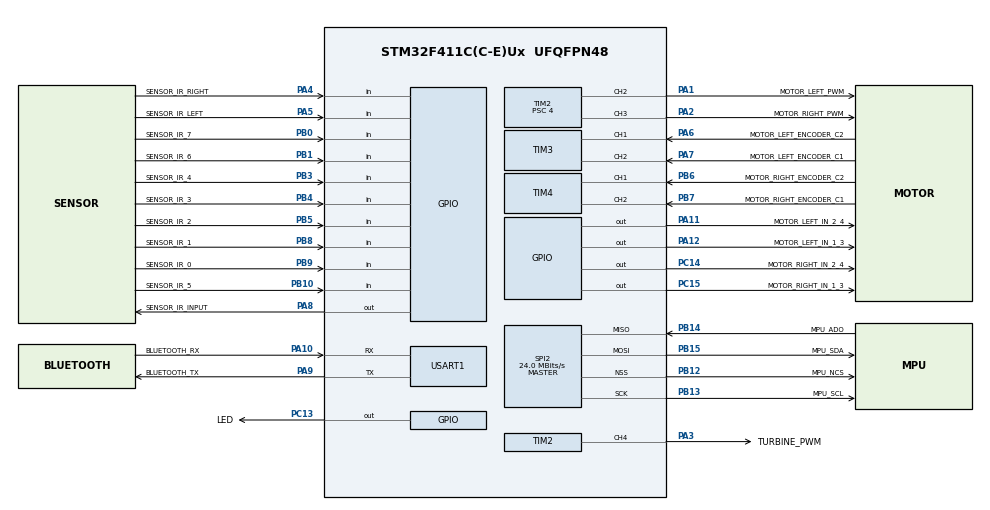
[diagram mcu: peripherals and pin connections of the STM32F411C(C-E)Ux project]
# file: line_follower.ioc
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Mcu.Family=STM32F4
Mcu.Name=STM32F411C(C-E)Ux
Mcu.Package=UFQFPN48
NVIC.PriorityGroup=NVIC_PRIORITYGROUP_4
NVIC.USART1_IRQn=true\:0\:0\:true\:false\:true\:true\:true\:true
PA1.GPIO_Label=MOTOR_LEFT_PWM
PA1.Signal=S_TIM2_CH2
PA10.GPIO_Label=BLUETOOTH_RX
PA10.Mode=Asynchronous
PA10.Signal=USART1_RX
PA11.GPIO_Label=MOTOR_LEFT_IN_2_4
PA11.Signal=GPIO_Output
PA12.GPIO_Label=MOTOR_LEFT_IN_1_3
PA12.Signal=GPIO_Output
PA2.GPIO_Label=MOTOR_RIGHT_PWM
PA2.Signal=S_TIM2_CH3
PA3.GPIO_Label=TURBINE_PWM
PA3.Signal=S_TIM2_CH4
PA4.GPIO_Label=SENSOR_IR_RIGHT
PA4.Signal=GPIO_Input
PA5.GPIO_Label=SENSOR_IR_LEFT
PA5.Signal=GPIO_Input
PA6.GPIO_Label=MOTOR_LEFT_ENCODER_C2
PA6.Signal=S_TIM3_CH1
PA7.GPIO_Label=MOTOR_LEFT_ENCODER_C1
PA7.Signal=S_TIM3_CH2
PA8.GPIO_Label=SENSOR_IR_INPUT
PA8.Signal=GPIO_Output
PA9.GPIO_Label=BLUETOOTH_TX
PA9.Mode=Asynchronous
PA9.Signal=USART1_TX
PB0.GPIO_Label=SENSOR_IR_7
PB0.Signal=GPIO_Input
PB1.GPIO_Label=SENSOR_IR_6
PB1.Signal=GPIO_Input
PB10.GPIO_Label=SENSOR_IR_5
PB10.Signal=GPIO_Input
PB12.GPIO_Label=MPU_NCS
PB12.Mode=NSS_Signal_Hard_Output
PB12.Signal=SPI2_NSS
PB13.GPIO_Label=MPU_SCL
PB13.Mode=Full_Duplex_Master
PB13.Signal=SPI2_SCK
PB14.GPIO_Label=MPU_ADO
PB14.Mode=Full_Duplex_Master
PB14.Signal=SPI2_MISO
PB15.GPIO_Label=MPU_SDA
PB15.Mode=Full_Duplex_Master
PB15.Signal=SPI2_MOSI
PB3.GPIO_Label=SENSOR_IR_4
PB3.Signal=GPIO_Input
PB4.GPIO_Label=SENSOR_IR_3
PB4.Signal=GPIO_Input
PB5.GPIO_Label=SENSOR_IR_2
PB5.Signal=GPIO_Input
PB6.GPIO_Label=MOTOR_RIGHT_ENCODER_C2
PB6.Signal=S_TIM4_CH1
PB7.GPIO_Label=MOTOR_RIGHT_ENCODER_C1
PB7.Signal=S_TIM4_CH2
PB8.GPIO_Label=SENSOR_IR_1
PB8.Signal=GPIO_Input
PB9.GPIO_Label=SENSOR_IR_0
PB9.Signal=GPIO_Input
PC13-ANTI_TAMP.GPIO_Label=LED
PC13-ANTI_TAMP.Signal=GPIO_Output
PC14-OSC32_IN.GPIO_Label=MOTOR_RIGHT_IN_2_4
PC14-OSC32_IN.Signal=GPIO_Output
PC15-OSC32_OUT.GPIO_Label=MOTOR_RIGHT_IN_1_3
PC15-OSC32_OUT.Signal=GPIO_Output
PH0\ -\ OSC_IN.Mode=HSE-External-Oscillator
PH0\ -\ OSC_IN.Signal=RCC_OSC_IN
PH1\ -\ OSC_OUT.Mode=HSE-External-Oscillator
PH1\ -\ OSC_OUT.Signal=RCC_OSC_OUT
ProjectManager.HeapSize=0x200
ProjectManager.StackSize=0x400
ProjectManager.TargetToolchain=CMake
RCC.48MHZClocksFreq_Value=48000000
RCC.AHBFreq_Value=96000000
RCC.APB1CLKDivider=RCC_HCLK_DIV2
RCC.APB1Freq_Value=48000000
RCC.APB1TimFreq_Value=96000000
RCC.APB2Freq_Value=96000000
RCC.APB2TimFreq_Value=96000000
RCC.CortexFreq_Value=96000000
RCC.HCLKFreq_Value=96000000
RCC.HSE_VALUE=25000000
RCC.HSI_VALUE=16000000
RCC.LSE_VALUE=32768
RCC.PLLM=25
RCC.PLLSourceVirtual=RCC_PLLSOURCE_HSE
RCC.SYSCLKFreq_VALUE=96000000
RCC.SYSCLKSource=RCC_SYSCLKSOURCE_PLLCLK
RCC.VCOOutputFreq_Value=192000000
SH.S_TIM2_CH2.0=TIM2_CH2,PWM Generation2 CH2
SH.S_TIM2_CH3.0=TIM2_CH3,PWM Generation3 CH3
SH.S_TIM2_CH4.0=TIM2_CH4,PWM Generation4 CH4
SH.S_TIM3_CH1.0=TIM3_CH1,Encoder_Interface
SH.S_TIM3_CH2.0=TIM3_CH2,Encoder_Interface
SH.S_TIM4_CH1.0=TIM4_CH1,Encoder_Interface
SH.S_TIM4_CH2.0=TIM4_CH2,Encoder_Interface
SPI2.BaudRatePrescaler=SPI_BAUDRATEPRESCALER_2
SPI2.CalculateBaudRate=24.0 MBits/s
SPI2.Direction=SPI_DIRECTION_2LINES
SPI2.Mode=SPI_MODE_MASTER
SPI2.VirtualNSS=VM_NSSHARD
SPI2.VirtualType=VM_MASTER
TIM2.Channel-PWM\ Generation2\ CH2=TIM_CHANNEL_2
TIM2.Channel-PWM\ Generation3\ CH3=TIM_CHANNEL_3
TIM2.Channel-PWM\ Generation4\ CH4=TIM_CHANNEL_4
TIM2.Period=999
TIM2.Prescaler=4
TIM3.EncoderMode=TIM_ENCODERMODE_TI12
TIM3.IC1Polarity=TIM_ICPOLARITY_FALLING
TIM4.EncoderMode=TIM_ENCODERMODE_TI12
TIM4.IC1Polarity=TIM_ICPOLARITY_FALLING
USART1.VirtualMode=VM_ASYNC
board=custom

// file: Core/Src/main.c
/* USER CODE BEGIN Header */
/**
 ******************************************************************************
 * @file           : main.c
 * @brief          : Main program body
 ******************************************************************************
 * @attention
 *
 * Copyright (c) 2025 STMicroelectronics.
 * All rights reserved.
 *
 * This software is licensed under terms that can be found in the LICENSE file
 * in the root directory of this software component.
 * If no LICENSE file comes with this software, it is provided AS-IS.
 *
 ******************************************************************************
 */
/* USER CODE END Header */
#include "main.h"

#include "gpio.h"
#include "spi.h"
#include "tim.h"
#include "usart.h"

/* USER CODE BEGIN Includes */
#include "state_machine/state_machine.h"

/* USER CODE END Includes */

void SystemClock_Config(void);

int main(void) {

    /* MCU
     * Configuration--------------------------------------------------------*/

    /* Reset of all peripherals, Initializes the Flash interface and the
     * Systick. */
    LL_APB2_GRP1_EnableClock(LL_APB2_GRP1_PERIPH_SYSCFG);
    LL_APB1_GRP1_EnableClock(LL_APB1_GRP1_PERIPH_PWR);

    /* System interrupt init*/
    NVIC_SetPriorityGrouping(NVIC_PRIORITYGROUP_4);

    /* SysTick_IRQn interrupt configuration */
    NVIC_SetPriority(SysTick_IRQn,
                     NVIC_EncodePriority(NVIC_GetPriorityGrouping(), 15, 0));

    /* Configure the system clock */
    SystemClock_Config();

    /* USER CODE BEGIN SysInit */
    /* Enable the ART accelerator: instruction cache, data cache and prefetch.
     * CubeMX emits PREFETCH_ENABLE / INSTRUCTION_CACHE_ENABLE /
     * DATA_CACHE_ENABLE as compile definitions, but only HAL_Init() consumes
     * them and this is an LL-only project, so they never take effect.
     * Valid as a plain OR only at boot: ACR resets to 0, so both caches are
     * already disabled and empty. */
    FLASH->ACR |= FLASH_ACR_ICEN | FLASH_ACR_DCEN | FLASH_ACR_PRFTEN;

    /* USER CODE END SysInit */

    /* Initialize all configured peripherals */
    MX_GPIO_Init();
    MX_USART1_UART_Init();
    MX_TIM2_Init();
    MX_TIM3_Init();
    MX_TIM4_Init();
    MX_SPI2_Init();
    /* USER CODE BEGIN 2 */

    run_state_machine();

    /* USER CODE END 2 */

    /* Infinite loop */
    while (1) {

    }
}

void SystemClock_Config(void) {
    LL_FLASH_SetLatency(LL_FLASH_LATENCY_3);
    while (LL_FLASH_GetLatency() != LL_FLASH_LATENCY_3) {
    }
    LL_PWR_SetRegulVoltageScaling(LL_PWR_REGU_VOLTAGE_SCALE1);
    LL_RCC_HSE_Enable();

    /* Wait till HSE is ready */
    while (LL_RCC_HSE_IsReady() != 1) {
    }
    LL_RCC_PLL_ConfigDomain_SYS(LL_RCC_PLLSOURCE_HSE, LL_RCC_PLLM_DIV_25, 192,
                                LL_RCC_PLLP_DIV_2);
    LL_RCC_PLL_Enable();

    /* Wait till PLL is ready */
    while (LL_RCC_PLL_IsReady() != 1) {
    }
    while (LL_PWR_IsActiveFlag_VOS() == 0) {
    }
    LL_RCC_SetAHBPrescaler(LL_RCC_SYSCLK_DIV_1);
    LL_RCC_SetAPB1Prescaler(LL_RCC_APB1_DIV_2);
    LL_RCC_SetAPB2Prescaler(LL_RCC_APB2_DIV_1);
    LL_RCC_SetSysClkSource(LL_RCC_SYS_CLKSOURCE_PLL);

    /* Wait till System clock is ready */
    while (LL_RCC_GetSysClkSource() != LL_RCC_SYS_CLKSOURCE_STATUS_PLL) {
    }
    LL_Init1msTick(96000000);
    LL_SetSystemCoreClock(96000000);
    LL_RCC_SetTIMPrescaler(LL_RCC_TIM_PRESCALER_TWICE);
}

void Error_Handler(void) {
    /* USER CODE BEGIN Error_Handler_Debug */
    /* User can add his own implementation to report the HAL error return state
     */
    __disable_irq();
    while (1) {
    }
    /* USER CODE END Error_Handler_Debug */
}
#ifdef USE_FULL_ASSERT
/**
 * @brief  Reports the name of the source file and the source line number
 *         where the assert_param error has occurred.
 * @param  file: pointer to the source file name
 * @param  line: assert_param error line source number
 * @retval None
 */
void assert_failed(uint8_t* file, uint32_t line) {
    /* USER CODE BEGIN 6 */
    /* User can add his own implementation to report the file name and line
             number, ex: printf("Wrong parameters value: file %s on line
       %d\r\n", file, line) */
    /* USER CODE END 6 */
}
#endif /* USE_FULL_ASSERT */
